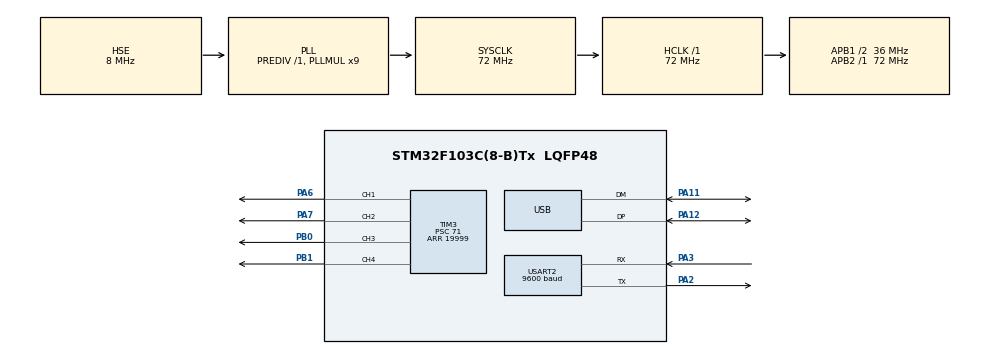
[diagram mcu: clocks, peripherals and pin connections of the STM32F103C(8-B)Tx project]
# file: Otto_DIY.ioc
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Mcu.Family=STM32F1
Mcu.Name=STM32F103C(8-B)Tx
Mcu.Package=LQFP48
NVIC.PriorityGroup=NVIC_PRIORITYGROUP_4
NVIC.TIM3_IRQn=true\:0\:0\:false\:false\:true\:true\:true
NVIC.USART2_IRQn=true\:0\:0\:false\:false\:true\:true\:true
NVIC.USB_LP_CAN1_RX0_IRQn=true\:0\:0\:true\:false\:true\:false\:true
PA11.Mode=Device
PA11.Signal=USB_DM
PA12.Mode=Device
PA12.Signal=USB_DP
PA13.Mode=Serial_Wire
PA13.Signal=SYS_JTMS-SWDIO
PA14.Mode=Serial_Wire
PA14.Signal=SYS_JTCK-SWCLK
PA2.Mode=Asynchronous
PA2.Signal=USART2_TX
PA3.Mode=Asynchronous
PA3.Signal=USART2_RX
PA5.Signal=ADCx_IN5
PA6.Signal=S_TIM3_CH1
PA7.Signal=S_TIM3_CH2
PB0.Signal=S_TIM3_CH3
PB1.Signal=S_TIM3_CH4
PB10.Signal=S_TIM2_CH3
PB11.Signal=S_TIM2_CH4
PD0-OSC_IN.Mode=HSE-External-Oscillator
PD0-OSC_IN.Signal=RCC_OSC_IN
PD1-OSC_OUT.Mode=HSE-External-Oscillator
PD1-OSC_OUT.Signal=RCC_OSC_OUT
ProjectManager.HeapSize=0x200
ProjectManager.StackSize=0x400
ProjectManager.TargetToolchain=STM32CubeIDE
RCC.AHBFreq_Value=72000000
RCC.APB1CLKDivider=RCC_HCLK_DIV2
RCC.APB1Freq_Value=36000000
RCC.APB1TimFreq_Value=72000000
RCC.APB2Freq_Value=72000000
RCC.APB2TimFreq_Value=72000000
RCC.HCLKFreq_Value=72000000
RCC.PLLMUL=RCC_PLL_MUL9
RCC.PLLSourceVirtual=RCC_PLLSOURCE_HSE
RCC.SYSCLKFreq_VALUE=72000000
RCC.SYSCLKSource=RCC_SYSCLKSOURCE_PLLCLK
RCC.USBFreq_Value=48000000
RCC.USBPrescaler=RCC_USBCLKSOURCE_PLL_DIV1_5
SH.ADCx_IN5.0=ADC1_IN5
SH.S_TIM2_CH3.0=TIM2_CH3
SH.S_TIM2_CH4.0=TIM2_CH4
SH.S_TIM3_CH1.0=TIM3_CH1,PWM Generation1 CH1
SH.S_TIM3_CH2.0=TIM3_CH2,PWM Generation2 CH2
SH.S_TIM3_CH3.0=TIM3_CH3,PWM Generation3 CH3
SH.S_TIM3_CH4.0=TIM3_CH4,PWM Generation4 CH4
TIM3.AutoReloadPreload=TIM_AUTORELOAD_PRELOAD_ENABLE
TIM3.Channel-PWM\ Generation1\ CH1=TIM_CHANNEL_1
TIM3.Channel-PWM\ Generation2\ CH2=TIM_CHANNEL_2
TIM3.Channel-PWM\ Generation3\ CH3=TIM_CHANNEL_3
TIM3.Channel-PWM\ Generation4\ CH4=TIM_CHANNEL_4
TIM3.Period=19999
TIM3.Prescaler=71
USART2.BaudRate=9600
USART2.VirtualMode=VM_ASYNC
USB_DEVICE.CLASS_NAME_FS=CDC
USB_DEVICE.VirtualMode=Cdc
USB_DEVICE.VirtualModeFS=Cdc_FS
VP_TIM3_VS_ClockSourceINT.Mode=Internal
VP_USB_DEVICE_VS_USB_DEVICE_CDC_FS.Mode=CDC_FS
board=custom

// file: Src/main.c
/* USER CODE BEGIN Header */
/**
  ******************************************************************************
  * @file           : main.c
  * @brief          : Main program body
  ******************************************************************************
  * @attention
  *
  * <h2><center>&copy; Copyright (c) 2019 STMicroelectronics.
  * All rights reserved.</center></h2>
  *
  * This software component is licensed by ST under Ultimate Liberty license
  * SLA0044, the "License"; You may not use this file except in compliance with
  * the License. You may obtain a copy of the License at:
  *                             www.st.com/SLA0044
  *
  ******************************************************************************
  */
/* USER CODE END Header */

#include "main.h"
#include "tim.h"
#include "usart.h"
#include "usb_device.h"
#include "gpio.h"

/* USER CODE BEGIN Includes */
#include "commands.h"
#include "bluetooth.h"
/* USER CODE END Includes */

void SystemClock_Config(void);

int main(void)
{

  /* MCU Configuration--------------------------------------------------------*/

  /* Reset of all peripherals, Initializes the Flash interface and the Systick. */
  HAL_Init();

  /* Configure the system clock */
  SystemClock_Config();

  /* Initialize all configured peripherals */
  MX_GPIO_Init();
  MX_USB_DEVICE_Init();
  MX_TIM3_Init();
  MX_USART2_UART_Init();
  /* USER CODE BEGIN 2 */
  limbs_init();
  tim_servo_start();
  bluetooh_init();
  commands_init();
  /* USER CODE END 2 */

  /* Infinite loop */
  /* USER CODE BEGIN WHILE */
  while (1){
	  commands_executNext();
    /* USER CODE END WHILE */

  }
}

void SystemClock_Config(void)
{
  RCC_OscInitTypeDef RCC_OscInitStruct = {0};
  RCC_ClkInitTypeDef RCC_ClkInitStruct = {0};
  RCC_PeriphCLKInitTypeDef PeriphClkInit = {0};

  /** Initializes the CPU, AHB and APB busses clocks
  */
  RCC_OscInitStruct.OscillatorType = RCC_OSCILLATORTYPE_HSE;
  RCC_OscInitStruct.HSEState = RCC_HSE_ON;
  RCC_OscInitStruct.HSEPredivValue = RCC_HSE_PREDIV_DIV1;
  RCC_OscInitStruct.HSIState = RCC_HSI_ON;
  RCC_OscInitStruct.PLL.PLLState = RCC_PLL_ON;
  RCC_OscInitStruct.PLL.PLLSource = RCC_PLLSOURCE_HSE;
  RCC_OscInitStruct.PLL.PLLMUL = RCC_PLL_MUL9;
  if (HAL_RCC_OscConfig(&RCC_OscInitStruct) != HAL_OK)
  {
    Error_Handler();
  }
  /** Initializes the CPU, AHB and APB busses clocks
  */
  RCC_ClkInitStruct.ClockType = RCC_CLOCKTYPE_HCLK|RCC_CLOCKTYPE_SYSCLK
                              |RCC_CLOCKTYPE_PCLK1|RCC_CLOCKTYPE_PCLK2;
  RCC_ClkInitStruct.SYSCLKSource = RCC_SYSCLKSOURCE_PLLCLK;
  RCC_ClkInitStruct.AHBCLKDivider = RCC_SYSCLK_DIV1;
  RCC_ClkInitStruct.APB1CLKDivider = RCC_HCLK_DIV2;
  RCC_ClkInitStruct.APB2CLKDivider = RCC_HCLK_DIV1;

  if (HAL_RCC_ClockConfig(&RCC_ClkInitStruct, FLASH_LATENCY_2) != HAL_OK)
  {
    Error_Handler();
  }
  PeriphClkInit.PeriphClockSelection = RCC_PERIPHCLK_USB;
  PeriphClkInit.UsbClockSelection = RCC_USBCLKSOURCE_PLL_DIV1_5;
  if (HAL_RCCEx_PeriphCLKConfig(&PeriphClkInit) != HAL_OK)
  {
    Error_Handler();
  }
}

void Error_Handler(void)
{
}

/************************ (C) COPYRIGHT STMicroelectronics *****END OF FILE****/
